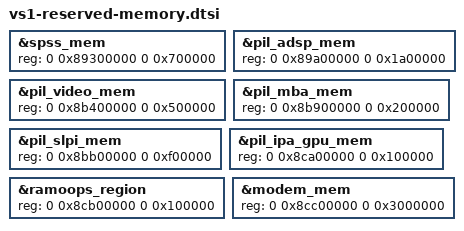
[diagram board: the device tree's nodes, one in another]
/* Copyright (c) 2018, Oculus VR. All rights reserved.
 *
 * This program is free software; you can redistribute it and/or modify
 * it under the terms of the GNU General Public License version 2 and
 * only version 2 as published by the Free Software Foundation.
 *
 * This program is distributed in the hope that it will be useful,
 * but WITHOUT ANY WARRANTY; without even the implied warranty of
 * MERCHANTABILITY or FITNESS FOR A PARTICULAR PURPOSE.  See the
 * GNU General Public License for more details.
 */

/*
 * Adjust reserved memory region sizes and position to reduce
 * total usage and fragmentation
 */
&spss_mem {
	reg = <0 0x89300000 0 0x700000>;
};

&pil_adsp_mem {
	reg = <0 0x89a00000 0 0x1a00000>;
};

&pil_video_mem {
	reg = <0 0x8b400000 0 0x500000>;
};

&pil_mba_mem {
	reg = <0 0x8b900000 0 0x200000>;
};

&pil_slpi_mem {
	reg = <0 0x8bb00000 0 0xf00000>;
};

&pil_ipa_gpu_mem {
	reg = <0 0x8ca00000 0 0x100000>;
};

&ramoops_region {
	reg = <0 0x8cb00000 0 0x100000>;
};

&modem_mem {
	/*
	 * Trimmed from 112 MB -> 48 MB
	 * Moving the modem base address breaks WLAN+BT
	 */
	reg = <0 0x8cc00000 0 0x3000000>;
};
